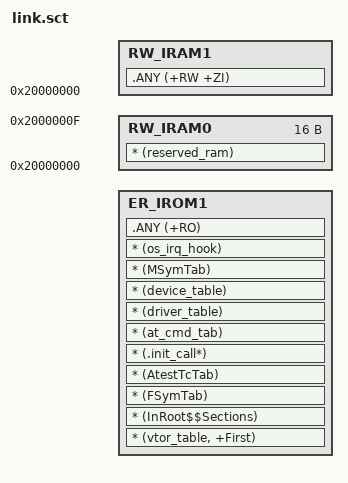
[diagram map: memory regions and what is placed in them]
; *************************************************************
; *** Scatter-Loading Description File generated by uVision ***
; *************************************************************

LR_IROM1  CODE_AREA_BASE   CODE_AREA_LENGTH {    ; load region size_region
  ER_IROM1  CODE_AREA_BASE CODE_AREA_LENGTH {  ; load address = execution address
   * (vtor_table, +First)
   * (InRoot$$Sections)
   * (FSymTab)
   * (AtestTcTab)
   * (.init_call*)
   * (at_cmd_tab)
   * (driver_table)
   * (device_table)
   * (MSymTab)
   * (os_irq_hook)
   .ANY (+RO)
  }

  RW_IRAM0 0x20000000 0x10  {  ; RW data
   * (reserved_ram)
  }

  RW_IRAM1 0x20000000 RAM_AREA_LENGTH {  ; RW data
   .ANY (+RW +ZI)
  }
}


